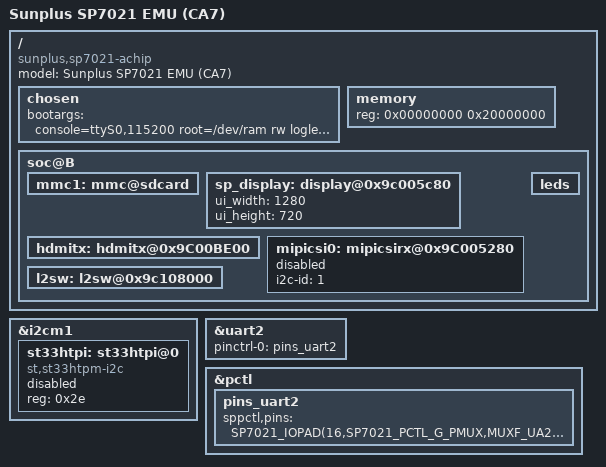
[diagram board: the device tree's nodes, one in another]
/dts-v1/;

#include "pentagram-sp7021-achip.dtsi"

#include <dt-bindings/interrupt-controller/arm-gic.h>

/ {
	model = "Sunplus SP7021 EMU (CA7)";
	compatible = "sunplus,sp7021-achip";

	chosen {
		bootargs = "console=ttyS0,115200 root=/dev/ram rw loglevel=8 user_debug=255 earlyprintk";
	};

	memory {
		reg = <0x00000000 0x20000000>; /* 512MB */
	};

	soc@B {
		mmc1: mmc@sdcard {
			status = "okay";
		};

		sp_display: display@0x9c005c80 {
			ui_width = <1280>;
			ui_height = <720>;
		};

		hdmitx: hdmitx@0x9C00BE00 {
			status = "okay";
		};

		mipicsi0: mipicsirx@0x9C005280 {
                        i2c-id = <1>;
			status = "disabled";
                };

		l2sw: l2sw@0x9c108000 {
			status = "okay";
		};

		leds {
			status = "okay";
		};
	};
};


&i2cm1 {
	status = "okay";

	st33htpi: st33htpi@0{
		compatible = "st,st33htpm-i2c";
		reg = <0x2e>;
		status="disabled";
	};
};

&uart2 {
	pinctrl-names = "default";
	pinctrl-0 = <&pins_uart2>;
	status = "okay";
};

&pctl {

	pins_uart2: pins_uart2 {
		sppctl,pins = <
			SP7021_IOPAD(16,SP7021_PCTL_G_PMUX,MUXF_UA2_TX,0)
			SP7021_IOPAD(17,SP7021_PCTL_G_PMUX,MUXF_UA2_RX,0)
			SP7021_IOPAD(18,SP7021_PCTL_G_PMUX,MUXF_UA2_RTS,0)
			SP7021_IOPAD(19,SP7021_PCTL_G_PMUX,MUXF_UA2_CTS,0)
		>;
	};
}; 

